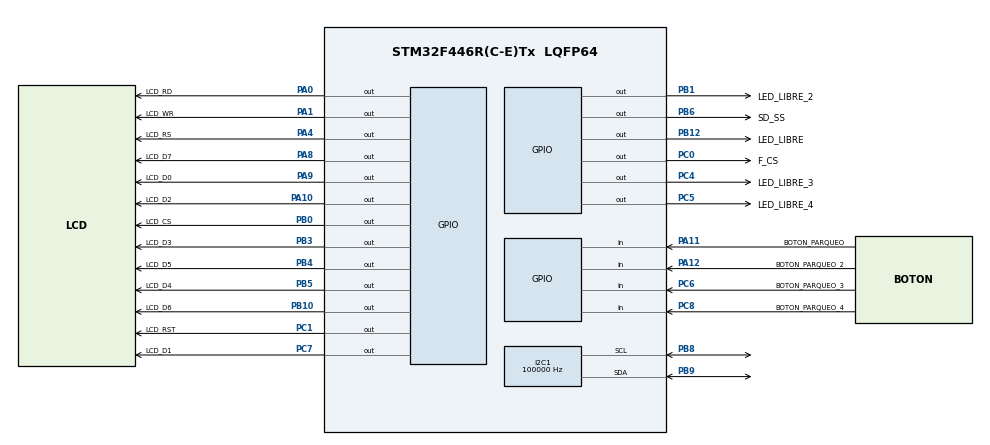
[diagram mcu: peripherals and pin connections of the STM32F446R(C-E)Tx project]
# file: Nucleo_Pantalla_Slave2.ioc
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I2C1.ClockSpeed=100000
I2C1.OwnAddress1=66
Mcu.Family=STM32F4
Mcu.Name=STM32F446R(C-E)Tx
Mcu.Package=LQFP64
NVIC.I2C1_ER_IRQn=true\:5\:0\:false\:false\:true\:true\:true\:true
NVIC.I2C1_EV_IRQn=true\:5\:0\:false\:false\:true\:true\:true\:true
NVIC.PriorityGroup=NVIC_PRIORITYGROUP_4
PA0-WKUP.GPIO_Label=LCD_RD
PA0-WKUP.GPIO_Speed=GPIO_SPEED_FREQ_HIGH
PA0-WKUP.PinState=GPIO_PIN_SET
PA0-WKUP.Signal=GPIO_Output
PA1.GPIO_Label=LCD_WR
PA1.GPIO_Speed=GPIO_SPEED_FREQ_HIGH
PA1.PinState=GPIO_PIN_SET
PA1.Signal=GPIO_Output
PA10.GPIO_Label=LCD_D2
PA10.GPIO_Speed=GPIO_SPEED_FREQ_HIGH
PA10.PinState=GPIO_PIN_RESET
PA10.Signal=GPIO_Output
PA11.GPIO_Label=BOTON_PARQUEO
PA11.GPIO_PuPd=GPIO_PULLUP
PA11.Signal=GPIO_Input
PA12.GPIO_Label=BOTON_PARQUEO_2
PA12.GPIO_PuPd=GPIO_PULLUP
PA12.Signal=GPIO_Input
PA13.Mode=Serial_Wire
PA13.Signal=SYS_JTMS-SWDIO
PA14.Mode=Serial_Wire
PA14.Signal=SYS_JTCK-SWCLK
PA4.GPIO_Label=LCD_RS
PA4.GPIO_Speed=GPIO_SPEED_FREQ_HIGH
PA4.PinState=GPIO_PIN_SET
PA4.Signal=GPIO_Output
PA8.GPIO_Label=LCD_D7
PA8.GPIO_Speed=GPIO_SPEED_FREQ_HIGH
PA8.PinState=GPIO_PIN_RESET
PA8.Signal=GPIO_Output
PA9.GPIO_Label=LCD_D0
PA9.GPIO_Speed=GPIO_SPEED_FREQ_HIGH
PA9.PinState=GPIO_PIN_RESET
PA9.Signal=GPIO_Output
PB0.GPIO_Label=LCD_CS
PB0.GPIO_Speed=GPIO_SPEED_FREQ_HIGH
PB0.PinState=GPIO_PIN_SET
PB0.Signal=GPIO_Output
PB1.GPIO_Label=LED_LIBRE_2
PB1.GPIO_Speed=GPIO_SPEED_FREQ_LOW
PB1.PinState=GPIO_PIN_RESET
PB1.Signal=GPIO_Output
PB10.GPIO_Label=LCD_D6
PB10.GPIO_Speed=GPIO_SPEED_FREQ_HIGH
PB10.PinState=GPIO_PIN_RESET
PB10.Signal=GPIO_Output
PB12.GPIO_Label=LED_LIBRE
PB12.GPIO_Speed=GPIO_SPEED_FREQ_LOW
PB12.PinState=GPIO_PIN_RESET
PB12.Signal=GPIO_Output
PB3.GPIO_Label=LCD_D3
PB3.GPIO_Speed=GPIO_SPEED_FREQ_HIGH
PB3.PinState=GPIO_PIN_RESET
PB3.Signal=GPIO_Output
PB4.GPIO_Label=LCD_D5
PB4.GPIO_Speed=GPIO_SPEED_FREQ_HIGH
PB4.PinState=GPIO_PIN_RESET
PB4.Signal=GPIO_Output
PB5.GPIO_Label=LCD_D4
PB5.GPIO_Speed=GPIO_SPEED_FREQ_HIGH
PB5.PinState=GPIO_PIN_RESET
PB5.Signal=GPIO_Output
PB6.GPIO_Label=SD_SS
PB6.GPIO_Speed=GPIO_SPEED_FREQ_LOW
PB6.PinState=GPIO_PIN_SET
PB6.Signal=GPIO_Output
PB8.Mode=I2C
PB8.Signal=I2C1_SCL
PB9.Mode=I2C
PB9.Signal=I2C1_SDA
PC0.GPIO_Label=F_CS
PC0.GPIO_Speed=GPIO_SPEED_FREQ_LOW
PC0.PinState=GPIO_PIN_SET
PC0.Signal=GPIO_Output
PC1.GPIO_Label=LCD_RST
PC1.GPIO_Speed=GPIO_SPEED_FREQ_HIGH
PC1.PinState=GPIO_PIN_SET
PC1.Signal=GPIO_Output
PC4.GPIO_Label=LED_LIBRE_3
PC4.GPIO_Speed=GPIO_SPEED_FREQ_LOW
PC4.PinState=GPIO_PIN_RESET
PC4.Signal=GPIO_Output
PC5.GPIO_Label=LED_LIBRE_4
PC5.GPIO_Speed=GPIO_SPEED_FREQ_LOW
PC5.PinState=GPIO_PIN_RESET
PC5.Signal=GPIO_Output
PC6.GPIO_Label=BOTON_PARQUEO_3
PC6.GPIO_PuPd=GPIO_PULLUP
PC6.Signal=GPIO_Input
PC7.GPIO_Label=LCD_D1
PC7.GPIO_Speed=GPIO_SPEED_FREQ_HIGH
PC7.PinState=GPIO_PIN_RESET
PC7.Signal=GPIO_Output
PC8.GPIO_Label=BOTON_PARQUEO_4
PC8.GPIO_PuPd=GPIO_PULLUP
PC8.Signal=GPIO_Input
ProjectManager.HeapSize=0x200
ProjectManager.StackSize=0x400
ProjectManager.TargetToolchain=STM32CubeIDE
RCC.CortexFreq_Value=16000000
RCC.USBFreq_Value=96000000
RCC.VCOOutputFreq_Value=192000000
board=custom

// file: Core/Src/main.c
/* USER CODE BEGIN Header */
/**
  ******************************************************************************
  * @file           : main.c
  * @brief          : Main program body
  ******************************************************************************
  * @attention
  *
  * Copyright (c) 2026 STMicroelectronics.
  * All rights reserved.
  *
  * This software is licensed under terms that can be found in the LICENSE file
  * in the root directory of this software component.
  * If no LICENSE file comes with this software, it is provided AS-IS.
  *
  ******************************************************************************
  */
/* USER CODE END Header */
#include "main.h"

/* USER CODE BEGIN Includes */
#include "parqueo.h"
#include "pantalla_parqueo.h"
#include "parqueo_i2c.h"
#include "neopixel_parqueo.h"
/* USER CODE END Includes */

I2C_HandleTypeDef hi2c1;

void SystemClock_Config(void);
static void MX_GPIO_Init(void);
static void MX_I2C1_Init(void);

int main(void)
{

  /* MCU Configuration--------------------------------------------------------*/

  /* Reset of all peripherals, Initializes the Flash interface and the Systick. */
  HAL_Init();

  /* Configure the system clock */
  SystemClock_Config();

  /* Initialize all configured peripherals */
  MX_GPIO_Init();
  MX_I2C1_Init();
  /* USER CODE BEGIN 2 */
  Parqueo_Init();
  ParqueoI2C_Init();
  NeoPixelParqueo_Init();
  PantallaParqueo_Init();
  /* USER CODE END 2 */

  /* Infinite loop */
  while (1)
  {

    /* USER CODE BEGIN 3 */
    Parqueo_Update();
    ParqueoI2C_Update();
    NeoPixelParqueo_Update();
    PantallaParqueo_Update();
  }
  /* USER CODE END 3 */
}

void SystemClock_Config(void)
{
  RCC_OscInitTypeDef RCC_OscInitStruct = {0};
  RCC_ClkInitTypeDef RCC_ClkInitStruct = {0};

  /** Configure the main internal regulator output voltage
  */
  __HAL_RCC_PWR_CLK_ENABLE();
  __HAL_PWR_VOLTAGESCALING_CONFIG(PWR_REGULATOR_VOLTAGE_SCALE3);

  /** Initializes the RCC Oscillators according to the specified parameters
  * in the RCC_OscInitTypeDef structure.
  */
  RCC_OscInitStruct.OscillatorType = RCC_OSCILLATORTYPE_HSI;
  RCC_OscInitStruct.HSIState = RCC_HSI_ON;
  RCC_OscInitStruct.HSICalibrationValue = RCC_HSICALIBRATION_DEFAULT;
  RCC_OscInitStruct.PLL.PLLState = RCC_PLL_NONE;
  if (HAL_RCC_OscConfig(&RCC_OscInitStruct) != HAL_OK)
  {
    Error_Handler();
  }

  /** Initializes the CPU, AHB and APB buses clocks
  */
  RCC_ClkInitStruct.ClockType = RCC_CLOCKTYPE_HCLK|RCC_CLOCKTYPE_SYSCLK
                              |RCC_CLOCKTYPE_PCLK1|RCC_CLOCKTYPE_PCLK2;
  RCC_ClkInitStruct.SYSCLKSource = RCC_SYSCLKSOURCE_HSI;
  RCC_ClkInitStruct.AHBCLKDivider = RCC_SYSCLK_DIV1;
  RCC_ClkInitStruct.APB1CLKDivider = RCC_HCLK_DIV1;
  RCC_ClkInitStruct.APB2CLKDivider = RCC_HCLK_DIV1;

  if (HAL_RCC_ClockConfig(&RCC_ClkInitStruct, FLASH_LATENCY_0) != HAL_OK)
  {
    Error_Handler();
  }
}

/**
  * @brief I2C1: STM esclavo 2, direccion de 7 bits 0x20, bus estandar de 100 kHz.
  */
static void MX_I2C1_Init(void)
{
  hi2c1.Instance = I2C1;
  hi2c1.Init.ClockSpeed = 100000;
  hi2c1.Init.DutyCycle = I2C_DUTYCYCLE_2;
  hi2c1.Init.OwnAddress1 = 0x42;
  hi2c1.Init.AddressingMode = I2C_ADDRESSINGMODE_7BIT;
  hi2c1.Init.DualAddressMode = I2C_DUALADDRESS_DISABLE;
  hi2c1.Init.OwnAddress2 = 0;
  hi2c1.Init.GeneralCallMode = I2C_GENERALCALL_DISABLE;
  hi2c1.Init.NoStretchMode = I2C_NOSTRETCH_DISABLE;
  if (HAL_I2C_Init(&hi2c1) != HAL_OK)
  {
    Error_Handler();
  }
}

static void MX_GPIO_Init(void)
{
  GPIO_InitTypeDef GPIO_InitStruct = {0};

  /* GPIO Ports Clock Enable */
  __HAL_RCC_GPIOC_CLK_ENABLE();
  __HAL_RCC_GPIOA_CLK_ENABLE();
  __HAL_RCC_GPIOB_CLK_ENABLE();

  /*Configure GPIO pin Output Level */
  HAL_GPIO_WritePin(GPIOC, F_CS_Pin|LCD_RST_Pin, GPIO_PIN_SET);

  /*Configure GPIO pin Output Level */
  HAL_GPIO_WritePin(GPIOA, LCD_RD_Pin|LCD_WR_Pin|LCD_RS_Pin, GPIO_PIN_SET);

  /*Configure GPIO pin Output Level */
  HAL_GPIO_WritePin(GPIOC, LED_LIBRE_3_Pin|LED_LIBRE_4_Pin|LCD_D1_Pin, GPIO_PIN_RESET);

  /*Configure GPIO pin Output Level */
  HAL_GPIO_WritePin(GPIOB, LCD_CS_Pin|SD_SS_Pin, GPIO_PIN_SET);

  /*Configure GPIO pin Output Level */
  HAL_GPIO_WritePin(GPIOB, LED_LIBRE_2_Pin|LCD_D6_Pin|LED_LIBRE_Pin|LCD_D3_Pin
                          |LCD_D5_Pin|LCD_D4_Pin, GPIO_PIN_RESET);

  /*Configure GPIO pin Output Level */
  HAL_GPIO_WritePin(GPIOA, LCD_D7_Pin|LCD_D0_Pin|LCD_D2_Pin, GPIO_PIN_RESET);

  /*Configure GPIO pins : F_CS_Pin LED_LIBRE_3_Pin LED_LIBRE_4_Pin */
  GPIO_InitStruct.Pin = F_CS_Pin|LED_LIBRE_3_Pin|LED_LIBRE_4_Pin;
  GPIO_InitStruct.Mode = GPIO_MODE_OUTPUT_PP;
  GPIO_InitStruct.Pull = GPIO_NOPULL;
  GPIO_InitStruct.Speed = GPIO_SPEED_FREQ_LOW;
  HAL_GPIO_Init(GPIOC, &GPIO_InitStruct);

  /*Configure GPIO pins : LCD_RST_Pin LCD_D1_Pin */
  GPIO_InitStruct.Pin = LCD_RST_Pin|LCD_D1_Pin;
  GPIO_InitStruct.Mode = GPIO_MODE_OUTPUT_PP;
  GPIO_InitStruct.Pull = GPIO_NOPULL;
  GPIO_InitStruct.Speed = GPIO_SPEED_FREQ_HIGH;
  HAL_GPIO_Init(GPIOC, &GPIO_InitStruct);

  /*Configure GPIO pins : LCD_RD_Pin LCD_WR_Pin LCD_RS_Pin LCD_D7_Pin
                           LCD_D0_Pin LCD_D2_Pin */
  GPIO_InitStruct.Pin = LCD_RD_Pin|LCD_WR_Pin|LCD_RS_Pin|LCD_D7_Pin
                          |LCD_D0_Pin|LCD_D2_Pin;
  GPIO_InitStruct.Mode = GPIO_MODE_OUTPUT_PP;
  GPIO_InitStruct.Pull = GPIO_NOPULL;
  GPIO_InitStruct.Speed = GPIO_SPEED_FREQ_HIGH;
  HAL_GPIO_Init(GPIOA, &GPIO_InitStruct);

  /*Configure GPIO pins : LCD_CS_Pin LCD_D6_Pin LCD_D3_Pin LCD_D5_Pin
                           LCD_D4_Pin */
  GPIO_InitStruct.Pin = LCD_CS_Pin|LCD_D6_Pin|LCD_D3_Pin|LCD_D5_Pin
                          |LCD_D4_Pin;
  GPIO_InitStruct.Mode = GPIO_MODE_OUTPUT_PP;
  GPIO_InitStruct.Pull = GPIO_NOPULL;
  GPIO_InitStruct.Speed = GPIO_SPEED_FREQ_HIGH;
  HAL_GPIO_Init(GPIOB, &GPIO_InitStruct);

  /*Configure GPIO pins : LED_LIBRE_2_Pin LED_LIBRE_Pin SD_SS_Pin */
  GPIO_InitStruct.Pin = LED_LIBRE_2_Pin|LED_LIBRE_Pin|SD_SS_Pin;
  GPIO_InitStruct.Mode = GPIO_MODE_OUTPUT_PP;
  GPIO_InitStruct.Pull = GPIO_NOPULL;
  GPIO_InitStruct.Speed = GPIO_SPEED_FREQ_LOW;
  HAL_GPIO_Init(GPIOB, &GPIO_InitStruct);

  /*Configure GPIO pins : BOTON_PARQUEO_3_Pin BOTON_PARQUEO_4_Pin */
  GPIO_InitStruct.Pin = BOTON_PARQUEO_3_Pin|BOTON_PARQUEO_4_Pin;
  GPIO_InitStruct.Mode = GPIO_MODE_INPUT;
  GPIO_InitStruct.Pull = GPIO_PULLUP;
  HAL_GPIO_Init(GPIOC, &GPIO_InitStruct);

  /*Configure GPIO pins : BOTON_PARQUEO_Pin BOTON_PARQUEO_2_Pin */
  GPIO_InitStruct.Pin = BOTON_PARQUEO_Pin|BOTON_PARQUEO_2_Pin;
  GPIO_InitStruct.Mode = GPIO_MODE_INPUT;
  GPIO_InitStruct.Pull = GPIO_PULLUP;
  HAL_GPIO_Init(GPIOA, &GPIO_InitStruct);

}

void Error_Handler(void)
{
  __disable_irq();
  while (1)
  {
  }
}
